VERSION "HIPFNNYYYYYYYYYYYYYYYYYYYYYYYYYYNNNNNNNNNN/4/%%%/4/'%**4NNN///"

NS_ :

BS_:

BU_:
VAL_TABLE_ DIAG_GenErrId_Values 0 "No error" 1 "Hardware" 2 "Software" 3 "Operation" 4 "Interface" 5 "Communication" 6 "External Resources" ;
VAL_TABLE_ DIAG_ErrGravity_Values 5 "Safety" 4 "Failure" 3 "Malfunction" 2 "Warning" 1 "Info" ;
VAL_TABLE_ DIAG_Cmd_Values 4 "SendGAIN_CLASS_msg" 2 "AbortSelfTest" 1 "SelfTestRequest" 0 "NotApplicable" ;
VAL_TABLE_ STO_FlightPhase_Values 12 "Parking/Post-flight" 11 "Taxi in" 10 "Landing" 9 "Approach" 8 "Cruise" 7 "Climb 2nd step" 6 "Climb 1st step" 5 "Take off 3rd step" 4 "Take off 2nd step" 3 "Take off 1st step" 2 "Taxi out" 1 "Parking/Pre-flight" 0 "NotApplicable" ;
VAL_TABLE_ STO_Units_Values 13 "Unit/-s" 12 "Lartge Cup/-s" 11 "Medium Cup/-s" 10 "Little Cup/-s" 9 "Flashes" 8 "Meal/-s" 7 "Fluid Ounces" 6 "Pints" 5 "Gallons" 4 "Liter" 3 "Pound" 2 "Ounces" 1 "kg" 0 "NotApplicable" ;
VAL_TABLE_ STO_Quality_Value 4 "Damaged" 3 "Low" 2 "Medium" 1 "High" 0 "Not applicable" ;
VAL_TABLE_ CSTA_NewState_Value 9 "StandBy Off" 8 "Error" 7 "Maintenance" 6 "Finished" 2 "StandBy On" ;
VAL_TABLE_ CMD_Cmd_Values 22 "Send_GAIN_Class_Msg" 21 "Send_STO_Msg" 20 "Send_CAT_Info_Msg" 4 "Keep warm" 3 "Pause catering process" 2 "Finish catering process" 1 "Start catering process" 0 "Not applicable" ;
VAL_TABLE_ STA_MGCU_StateVal 4 "Error" 3 "Maintenance" 2 "Operational" ;
VAL_TABLE_ AR812MsgCode 28 "STA_GAIN" 26 "STA_MGCU" 24 "DTA" 22 "DIAG" 20 "DIAG_CMD" 18 "PBM" 16 "PBR" 14 "GAIN_PT" 12 "FLIGHT_INFO" 10 "GAIN_CLASS" 8 "STO" 6 "CAT_INFO" 4 "CSTA" 2 "CMD" ;
VAL_TABLE_ DIAG_SpecErrId_Values 50 "Pin programming error" 43 "Phase C loss" 42 "Phase B loss" 41 "Phase A loss" 40 "Phase loss" 31 "Configuration error" 30 "Self-test aborted" 24 "Overflow" 23 "Message sequence interrupted" 22 "Command error" 21 "Invalid message" 20 "Invalid device ID" 15 "Checksum error" 14 "Data transfer denied (already on process)" 13 "File already exists" 12 "Allocation exceeded" 11 "Data transmission counter error" 10 "Data transmission interrupted" 2 "Catering Process Quality Damaged" 1 "Undefined Error" 0 "No error" ;

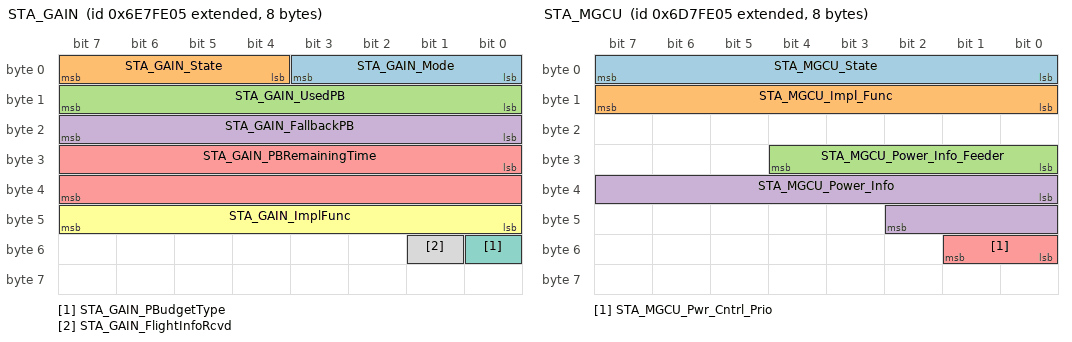
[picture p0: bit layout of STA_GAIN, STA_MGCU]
BO_ 2263350789 STA_GAIN: 8 Vector__XXX
 SG_ STA_GAIN_Mode : 0|4@1+ (1,0) [0|0] "" Vector__XXX
 SG_ STA_GAIN_State : 4|4@1+ (1,0) [0|0] "" Vector__XXX
 SG_ STA_GAIN_UsedPB : 8|8@1+ (50,0) [0|12750] "" Vector__XXX
 SG_ STA_GAIN_FallbackPB : 16|8@1+ (1,0) [0|0] "" Vector__XXX
 SG_ STA_GAIN_PBRemainingTime : 24|16@1+ (1,0) [0|0] "" Vector__XXX
 SG_ STA_GAIN_ImplFunc : 40|8@1+ (1,0) [0|0] "" Vector__XXX
 SG_ STA_GAIN_PBudgetType : 48|1@1+ (1,0) [0|0] "" Vector__XXX
 SG_ STA_GAIN_FlightInfoRcvd : 49|1@1+ (1,0) [0|0] "" Vector__XXX

BO_ 2262302213 STA_MGCU: 8 Vector__XXX
 SG_ STA_MGCU_State : 0|8@1+ (1,0) [0|0] "" Vector__XXX
 SG_ STA_MGCU_Impl_Func : 8|8@1+ (1,0) [0|0] "" Vector__XXX
 SG_ STA_MGCU_Power_Info_Feeder : 24|5@1+ (1,0) [0|0] "" Vector__XXX
 SG_ STA_MGCU_Power_Info : 32|11@1+ (1,0) [0|0] "" Vector__XXX
 SG_ STA_MGCU_Pwr_Cntrl_Prio : 48|2@1+ (1,0) [0|0] "" Vector__XXX

BO_ 2496134661 DTA: 8 Vector__XXX
 SG_ DTA_Descr_DataPacketNr m0 : 11|4@1- (1,0) [0|15] "" Vector__XXX
 SG_ DTA_Descr_HandshakeType m1 : 11|4@1+ (1,0) [0|15] "" Vector__XXX
 SG_ DTA_SrcLevelId : 0|5@1+ (1,0) [0|0] "" Vector__XXX
 SG_ DTA_SrcDeviceId : 5|5@1+ (1,0) [0|0] "" Vector__XXX
 SG_ DTA_Descr_Type M : 10|1@1+ (1,0) [0|1] "" Vector__XXX

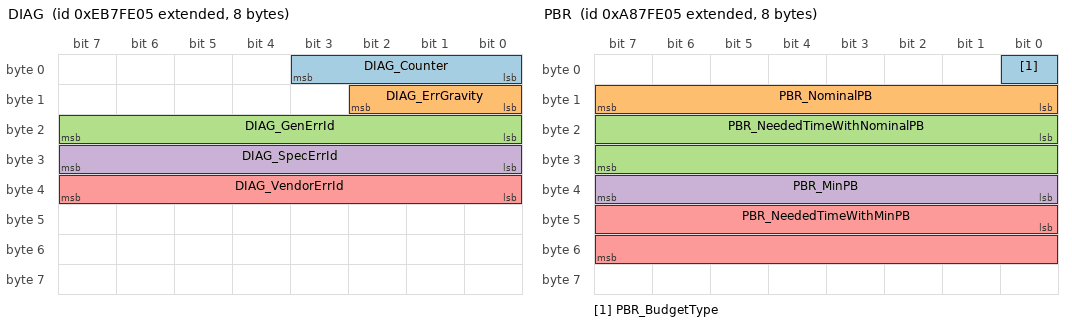
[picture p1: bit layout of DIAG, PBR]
BO_ 2394422789 DIAG: 8 Vector__XXX
 SG_ DIAG_Counter : 0|4@1+ (1,0) [0|0] "" Vector__XXX
 SG_ DIAG_ErrGravity : 8|3@1+ (1,0) [0|0] "" Vector__XXX
 SG_ DIAG_GenErrId : 16|8@1+ (1,0) [0|0] "" Vector__XXX
 SG_ DIAG_SpecErrId : 24|8@1+ (1,0) [0|0] "" Vector__XXX
 SG_ DIAG_VendorErrId : 32|8@1+ (1,0) [0|0] "" Vector__XXX

BO_ 2494037509 DIAG_CMD: 8 Vector__XXX
 SG_ DIAG_CMD_Cmd : 0|8@1+ (1,0) [0|0] "" Vector__XXX

BO_ 2358771205 PBM: 8 Vector__XXX
 SG_ PBM_PBMax : 0|8@1+ (50,0) [0|12750] "VA" Vector__XXX
 SG_ PBM_Time : 8|16@1+ (1,0) [0|0] "" Vector__XXX

BO_ 2324168197 PBR: 8 Vector__XXX
 SG_ PBR_BudgetType : 0|1@1+ (1,0) [0|0] "" Vector__XXX
 SG_ PBR_NominalPB : 8|8@1+ (50,0) [0|12750] "VA" Vector__XXX
 SG_ PBR_NeededTimeWithNominalPB : 16|16@1+ (1,0) [0|0] "sec" Vector__XXX
 SG_ PBR_MinPB : 32|8@1+ (50,0) [0|12750] "VA" Vector__XXX
 SG_ PBR_NeededTimeWithMinPB : 40|16@1+ (1,0) [0|0] "sec" Vector__XXX

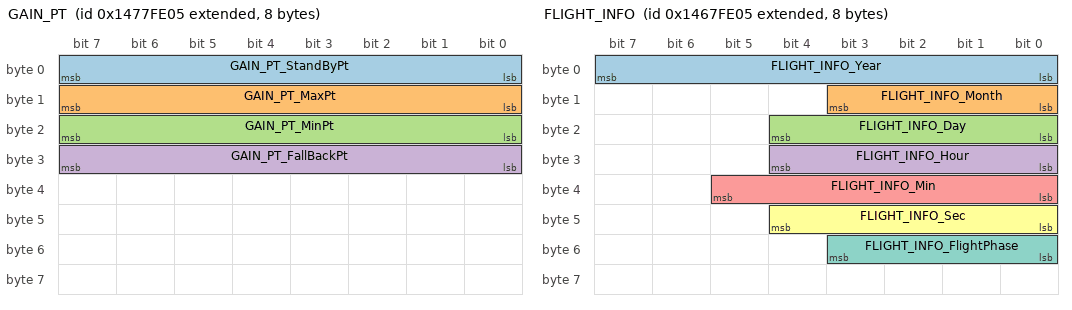
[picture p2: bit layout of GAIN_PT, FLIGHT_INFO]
BO_ 2490891781 GAIN_PT: 8 Vector__XXX
 SG_ GAIN_PT_StandByPt : 0|8@1+ (5,0) [0|1275] "VA" Vector__XXX
 SG_ GAIN_PT_MaxPt : 8|8@1+ (50,0) [0|0] "VA" Vector__XXX
 SG_ GAIN_PT_MinPt : 16|8@1+ (50,0) [0|12750] "VA" Vector__XXX
 SG_ GAIN_PT_FallBackPt : 24|8@1+ (50,0) [0|12750] "VA" Vector__XXX

BO_ 2489843205 FLIGHT_INFO: 8 Vector__XXX
 SG_ FLIGHT_INFO_Year : 0|8@1+ (1,2000) [2000|2255] "" Vector__XXX
 SG_ FLIGHT_INFO_Month : 8|4@1+ (1,0) [0|0] "" Vector__XXX
 SG_ FLIGHT_INFO_Day : 16|5@1+ (1,0) [0|0] "" Vector__XXX
 SG_ FLIGHT_INFO_Hour : 24|5@1+ (1,0) [0|0] "" Vector__XXX
 SG_ FLIGHT_INFO_Min : 32|6@1+ (1,0) [0|0] "" Vector__XXX
 SG_ FLIGHT_INFO_Sec : 40|5@1+ (1,0) [0|0] "" Vector__XXX
 SG_ FLIGHT_INFO_FlightPhase : 48|4@1+ (1,0) [0|0] "" Vector__XXX

BO_ 2488794629 GAIN_CLASS: 8 Vector__XXX
 SG_ GAIN_CLASS_DevClass : 0|5@1+ (1,0) [0|0] "" Vector__XXX
 SG_ GAIN_CLASS_DevGroup : 8|5@1+ (1,0) [0|0] "" Vector__XXX

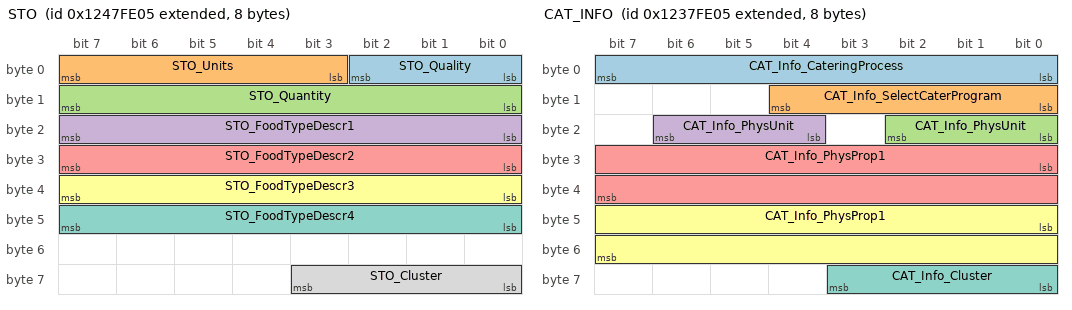
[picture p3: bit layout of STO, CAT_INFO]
BO_ 2454191621 STO: 8 Vector__XXX
 SG_ STO_Quality : 0|3@1+ (1,0) [0|0] "" Vector__XXX
 SG_ STO_Units : 3|5@1+ (1,0) [0|31] "" Vector__XXX
 SG_ STO_Quantity : 8|8@1+ (1,0) [0|0] "" Vector__XXX
 SG_ STO_FoodTypeDescr1 : 16|8@1+ (1,0) [0|0] "" Vector__XXX
 SG_ STO_FoodTypeDescr2 : 24|8@1+ (1,0) [0|0] "" Vector__XXX
 SG_ STO_FoodTypeDescr3 : 32|8@1+ (1,0) [0|0] "" Vector__XXX
 SG_ STO_FoodTypeDescr4 : 40|8@1+ (1,0) [0|0] "" Vector__XXX
 SG_ STO_Cluster : 56|4@1+ (1,0) [0|0] "" Vector__XXX

BO_ 2453143045 CAT_INFO: 8 Vector__XXX
 SG_ CAT_Info_CateringProcess : 0|8@1+ (1,0) [0|0] "" Vector__XXX
 SG_ CAT_Info_SelectCaterProgram : 8|5@1+ (1,0) [0|0] "" Vector__XXX
 SG_ CAT_Info_PhysUnit : 16|3@1+ (1,0) [0|0] "" Vector__XXX
 SG_ CAT_Info_PhysUnit : 20|3@1+ (1,0) [0|0] "" Vector__XXX
 SG_ CAT_Info_PhysProp1 : 24|16@1+ (1,0) [0|0] "" Vector__XXX
 SG_ CAT_Info_PhysProp1 : 40|16@1+ (1,0) [0|0] "" Vector__XXX
 SG_ CAT_Info_Cluster : 56|4@1+ (1,0) [0|0] "" Vector__XXX

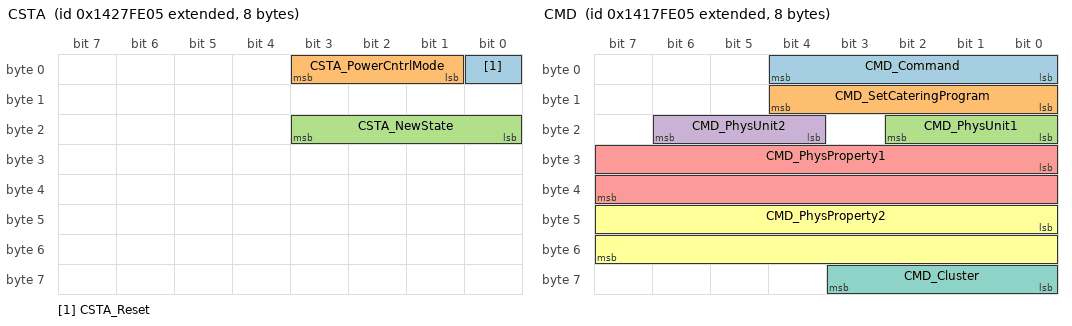
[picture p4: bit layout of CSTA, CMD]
BO_ 2485648901 CSTA: 8 Vector__XXX
 SG_ CSTA_Reset : 0|1@1+ (1,0) [0|0] "" Vector__XXX
 SG_ CSTA_PowerCntrlMode : 1|3@1+ (1,0) [0|0] "" Vector__XXX
 SG_ CSTA_NewState : 16|4@1+ (1,0) [0|0] "" Vector__XXX

BO_ 2484600325 CMD: 8 Vector__XXX
 SG_ CMD_Command : 0|5@1+ (1,0) [0|0] "" Vector__XXX
 SG_ CMD_SetCateringProgram : 8|5@1+ (1,0) [0|0] "" Vector__XXX
 SG_ CMD_PhysUnit1 : 16|3@1+ (1,0) [0|0] "" Vector__XXX
 SG_ CMD_PhysUnit2 : 20|3@1+ (1,0) [0|0] "" Vector__XXX
 SG_ CMD_PhysProperty1 : 24|16@1+ (1,0) [0|0] "" Vector__XXX
 SG_ CMD_PhysProperty2 : 40|16@1+ (1,0) [0|0] "" Vector__XXX
 SG_ CMD_Cluster : 56|4@1+ (1,0) [0|0] "" Vector__XXX

BA_DEF_ BU_  "GAINCFG12_1_2_GAIN_COUNTER_THRES" HEX 0 255;
BA_DEF_ BU_  "GAINCFG12_1_1_GAIN_COUNTER_DELTA" HEX 0 255;
BA_DEF_ BU_  "GAINCFG12_1_0_GAIN_COUNTER_DELTA" HEX 0 255;
BA_DEF_ BU_  "MGCUCFG12_0_2_MGCU_COUNTER_THRES" HEX 0 255;
BA_DEF_ BU_  "MGCUCFG12_0_1_MGCU_COUNTER_DELTA" HEX 0 255;
BA_DEF_ BU_  "MGCUCFG12_0_0_MGCU_COUNTER_DELTA" HEX 0 255;
BA_DEF_ BU_  "GAINCFG11_1_1_DECENTRALIZED_RAND" HEX 0 65535;
BA_DEF_ BU_  "GAINCFG11_1_0_DECENTRALIZED_RAND" HEX 0 65535;
BA_DEF_ BU_  "GAINCFG11_0_1_DECENTRALIZED_SYNC" HEX 0 65535;
BA_DEF_ BU_  "GAINCFG11_0_0_DECENTRALIZED_SYNC" HEX 0 65535;
BA_DEF_ BU_  "MGCUCFG10_8_2_INHIBIT_TIMER_STA_" HEX 0 65535;
BA_DEF_ BU_  "MGCUCFG10_8_1_TIMER_STA_TIMEOUT_" HEX 0 65535;
BA_DEF_ BU_  "MGCUCFG10_8_0_TIMER_STA_MGCU" HEX 0 65535;
BA_DEF_ BU_  "MGCUCFG10_7_0_INHIBIT_TIMER_DIAG" HEX 0 65535;
BA_DEF_ BU_  "MGCUCFG10_6_0_INHIBIT_TIMER_PBM" HEX 0 65535;
BA_DEF_ BU_  "MGCUCFG10_5_0_INHIBIT_TIMER_FLIG" HEX 0 65535;
BA_DEF_ BU_  "MGCUCFG10_4_0_INHIBIT_TIMER_CSTA" HEX 0 65535;
BA_DEF_ BU_  "MGCUCFG10_3_0_INHIBIT_TIMER_CMD" HEX 0 65535;
BA_DEF_ BU_  "MGCUCFG10_2_0_SEQUENCE_TIMEOUT_T" HEX 0 65535;
BA_DEF_ BU_  "MGCUCFG10_1_0_INHIBIT_TIMER_DTA" HEX 0 65535;
BA_DEF_ BU_  "MGCUCFG10_0_0_INHIBIT_TIMER_DIAG" HEX 0 65535;
BA_DEF_ BU_  "GAINCFG9_9_2_INHIBIT_TIMER_STA_G" HEX 0 65535;
BA_DEF_ BU_  "GAINCFG9_9_1_TIMER_STA_TIMEOUT_G" HEX 0 65535;
BA_DEF_ BU_  "GAINCFG9_9_0_TIMER_STA_GAIN" HEX 0 65535;
BA_DEF_ BU_  "GAINCFG9_8_0_INHIBIT_TIMER_PBR" HEX 0 65535;
BA_DEF_ BU_  "GAINCFG9_7_0_INHIBIT_TIMER_GAIN_" HEX 0 65535;
BA_DEF_ BU_  "GAINCFG9_6_0_FLIGHT_INFO_RECEIVE" HEX 0 65535;
BA_DEF_ BU_  "GAINCFG9_5_0_INHIBIT_TIMER_GAIN_" HEX 0 65535;
BA_DEF_ BU_  "GAINCFG9_4_0_INHIBIT_TIMER_STO" HEX 0 65535;
BA_DEF_ BU_  "GAINCFG9_3_0_INHIBIT_TIMER_CAT_I" HEX 0 65535;
BA_DEF_ BU_  "GAINCFG9_2_0_SEQUENCE_TIMEOUT_TI" HEX 0 65535;
BA_DEF_ BU_  "GAINCFG7_X_6_SIGN_PHYSICAL_UNIT_" ENUM  "plus","minus";
BA_DEF_ BU_  "GAINCFG7_X_3_SIGN_PHYSICAL_UNIT_" ENUM  "plus","minus";
BA_DEF_ BU_  "GAINCFG5_3_0_DEVICE_CLASS" ENUM  "Specific (Other)","Oven","Beverage Maker","Refrigerator","Waste Handling","Reserved";
BA_DEF_ BU_  "GAINCFG5_0_0_FALLBACK_TYPE" ENUM  "Secondary","Primary";
BA_DEF_ BU_  "GAINCFG1_0_0_DEVICE_STANDARD" ENUM  "Reserved","ARINC","ATLAS","KSSU","Reserved","Reserved","Reserved","Reserved","Reserved","Reserved","Reserved","Reserved","Reserved","Reserved","Reserved","Reserved";
BA_DEF_  "ProtocolType" STRING ;
BA_DEF_  "BusType" STRING ;
BA_DEF_DEF_  "GAINCFG12_1_2_GAIN_COUNTER_THRES" 1;
BA_DEF_DEF_  "GAINCFG12_1_1_GAIN_COUNTER_DELTA" 1;
BA_DEF_DEF_  "GAINCFG12_1_0_GAIN_COUNTER_DELTA" 1;
BA_DEF_DEF_  "MGCUCFG12_0_2_MGCU_COUNTER_THRES" 1;
BA_DEF_DEF_  "MGCUCFG12_0_1_MGCU_COUNTER_DELTA" 1;
BA_DEF_DEF_  "MGCUCFG12_0_0_MGCU_COUNTER_DELTA" 1;
BA_DEF_DEF_  "GAINCFG11_1_1_DECENTRALIZED_RAND" 200;
BA_DEF_DEF_  "GAINCFG11_1_0_DECENTRALIZED_RAND" 50;
BA_DEF_DEF_  "GAINCFG11_0_1_DECENTRALIZED_SYNC" 1000;
BA_DEF_DEF_  "GAINCFG11_0_0_DECENTRALIZED_SYNC" 1000;
BA_DEF_DEF_  "MGCUCFG10_8_2_INHIBIT_TIMER_STA_" 1000;
BA_DEF_DEF_  "MGCUCFG10_8_1_TIMER_STA_TIMEOUT_" 2200;
BA_DEF_DEF_  "MGCUCFG10_8_0_TIMER_STA_MGCU" 2000;
BA_DEF_DEF_  "MGCUCFG10_7_0_INHIBIT_TIMER_DIAG" 1000;
BA_DEF_DEF_  "MGCUCFG10_6_0_INHIBIT_TIMER_PBM" 1000;
BA_DEF_DEF_  "MGCUCFG10_5_0_INHIBIT_TIMER_FLIG" 1000;
BA_DEF_DEF_  "MGCUCFG10_4_0_INHIBIT_TIMER_CSTA" 1000;
BA_DEF_DEF_  "MGCUCFG10_3_0_INHIBIT_TIMER_CMD" 1000;
BA_DEF_DEF_  "MGCUCFG10_2_0_SEQUENCE_TIMEOUT_T" 5000;
BA_DEF_DEF_  "MGCUCFG10_1_0_INHIBIT_TIMER_DTA" 50;
BA_DEF_DEF_  "MGCUCFG10_0_0_INHIBIT_TIMER_DIAG" 1000;
BA_DEF_DEF_  "GAINCFG9_9_2_INHIBIT_TIMER_STA_G" 1000;
BA_DEF_DEF_  "GAINCFG9_9_1_TIMER_STA_TIMEOUT_G" 2200;
BA_DEF_DEF_  "GAINCFG9_9_0_TIMER_STA_GAIN" 2000;
BA_DEF_DEF_  "GAINCFG9_8_0_INHIBIT_TIMER_PBR" 1000;
BA_DEF_DEF_  "GAINCFG9_7_0_INHIBIT_TIMER_GAIN_" 1000;
BA_DEF_DEF_  "GAINCFG9_6_0_FLIGHT_INFO_RECEIVE" 6200;
BA_DEF_DEF_  "GAINCFG9_5_0_INHIBIT_TIMER_GAIN_" 6000;
BA_DEF_DEF_  "GAINCFG9_4_0_INHIBIT_TIMER_STO" 6000;
BA_DEF_DEF_  "GAINCFG9_3_0_INHIBIT_TIMER_CAT_I" 1000;
BA_DEF_DEF_  "GAINCFG9_2_0_SEQUENCE_TIMEOUT_TI" 5000;
BA_DEF_DEF_  "GAINCFG7_X_6_SIGN_PHYSICAL_UNIT_" "plus";
BA_DEF_DEF_  "GAINCFG7_X_3_SIGN_PHYSICAL_UNIT_" "plus";
BA_DEF_DEF_  "GAINCFG5_3_0_DEVICE_CLASS" "Specific (Other)";
BA_DEF_DEF_  "GAINCFG5_0_0_FALLBACK_TYPE" "Secondary";
BA_DEF_DEF_  "GAINCFG1_0_0_DEVICE_STANDARD" "ARINC";
BA_DEF_DEF_  "ProtocolType" "ARINC812";
BA_DEF_DEF_  "BusType" "CAN";
VAL_ 2262302213 STA_MGCU_State 4 "Error" 3 "Maintenance" 2 "Operational" ;
VAL_ 2496134661 DTA_Descr_DataPacketNr 15 "16th data packet" 14 "15th data packet" 13 "14th data packet" 12 "13th data packet" 11 "12th data packet" 10 "11th data packet" 9 "10th data packet" 8 "9th data packet" 7 "8th data packet" 6 "7th data packet" 5 "6th data packet" 4 "5th data packet" 3 "4th data packet" 2 "3rd data packet" 1 "2nd data packet" 0 "1st data packet" ;
VAL_ 2496134661 DTA_Descr_HandshakeType 10 "EOT" 9 "Abort" 8 "Retry all blocks" 7 "Retry last block" 6 "Acknowledge" 5 "RFT" 4 "AOT Download Memory mech." 3 "AOT Download Block mech." 2 "AOT Upload Memory mech." 1 "AOT Upload Block mech." 0 "Reserved" ;
VAL_ 2496134661 DTA_Descr_Type 1 "Handshake frame" 0 "Data frame" ;
VAL_ 2394422789 DIAG_ErrGravity 5 "Safety" 4 "Failure" 3 "Malfunction" 2 "Warning" 1 "Info" ;
VAL_ 2394422789 DIAG_GenErrId 0 "No error" 1 "Hardware" 2 "Software" 3 "Operation" 4 "Interface" 5 "Communication" 6 "External Resources" ;
VAL_ 2394422789 DIAG_SpecErrId 50 "Pin programming error" 43 "Phase C loss" 42 "Phase B loss" 41 "Phase A loss" 40 "Phase loss" 31 "Configuration error" 30 "Self-test aborted" 24 "Overflow" 23 "Message sequence interrupted" 22 "Command error" 21 "Invalid message" 20 "Invalid device ID" 15 "Checksum error" 14 "Data transfer denied (already on process)" 13 "File already exists" 12 "Allocation exceeded" 11 "Data transmission counter error" 10 "Data transmission interrupted" 2 "Catering Process Quality Damaged" 1 "Undefined Error" 0 "No error" ;
VAL_ 2494037509 DIAG_CMD_Cmd 4 "SendGAIN_CLASS_msg" 2 "AbortSelfTest" 1 "SelfTestRequest" 0 "NotApplicable" ;
VAL_ 2489843205 FLIGHT_INFO_FlightPhase 12 "Parking/Post-flight" 11 "Taxi in" 10 "Landing" 9 "Approach" 8 "Cruise" 7 "Climb 2nd step" 6 "Climb 1st step" 5 "Take off 3rd step" 4 "Take off 2nd step" 3 "Take off 1st step" 2 "Taxi out" 1 "Parking/Pre-flight" 0 "NotApplicable" ;
VAL_ 2454191621 STO_Quality 4 "Damaged" 3 "Low" 2 "Medium" 1 "High" 0 "Not applicable" ;
VAL_ 2454191621 STO_Units 13 "Unit/-s" 12 "Lartge Cup/-s" 11 "Medium Cup/-s" 10 "Little Cup/-s" 9 "Flashes" 8 "Meal/-s" 7 "Fluid Ounces" 6 "Pints" 5 "Gallons" 4 "Liter" 3 "Pound" 2 "Ounces" 1 "kg" 0 "NotApplicable" ;
VAL_ 2485648901 CSTA_NewState 9 "StandBy Off" 8 "Error" 7 "Maintenance" 6 "Finished" 2 "StandBy On" ;
VAL_ 2484600325 CMD_Command 22 "Send_GAIN_Class_Msg" 21 "Send_STO_Msg" 20 "Send_CAT_Info_Msg" 4 "Keep warm" 3 "Pause catering process" 2 "Finish catering process" 1 "Start catering process" 0 "Not applicable" ;
